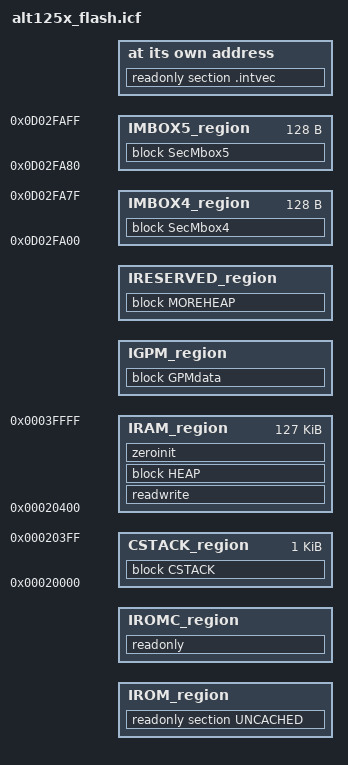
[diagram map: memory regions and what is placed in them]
/*###ICF### Section handled by ICF editor, don't touch! ****/
/*-Editor annotation file-*/
/* IcfEditorFile="$TOOLKIT_DIR$\config\ide\IcfEditor\cortex_v1_4.xml" */

include "defs.icf";

/* The base address for MCU firmware on flash */
define symbol __MCU_MTD_PARTITION_BASE__ = 0x08000000;
export symbol __MCU_MTD_PARTITION_BASE__;

/* The header size for MCU firmware */
define symbol __HEADER_SIZE__ = 0x200;

/* An instruction cache is present on the I-CODE bus for
 * address 0x1000_0000 to 0x1FFF_FFFF whereas
 * address 0x0000_0000 to 0x0FFF_FFFF is used for direct instruction fetching. */


/* Reserve a memory region for the .uncached section (direct access) */
define symbol __UNCACHED_SIZE__ = 0x400;
define symbol __UNCACHED_ORIGIN__ = __MCU_MTD_PARTITION_BASE__ + __MCU_MTD_PARTITION_OFFSET__ + __HEADER_SIZE__;

/* To leverage instruction cache, use address 0x1000_0000 to 0x1FFF_FFFF */
define symbol __FLASH_ORIGIN__ = __UNCACHED_ORIGIN__ + __UNCACHED_SIZE__ + 0x10000000;
define symbol __FLASH_END__ = __FLASH_ORIGIN__ + __MCU_MTD_PARTITION_SIZE__ - __UNCACHED_SIZE__ - __HEADER_SIZE__ + 0x10000000 - 1;

/* A part of the GPM memory is used as an extended heap.
 * By defining __RESERVED_GPM_RAM_SIZE__, one can adjust the size of the second HEAP (default to half of the GPM RAM).
 */
if (!isdefinedsymbol(__RESERVED_GPM_RAM_SIZE__)) {
  define symbol __RESERVED_GPM_RAM_SIZE__ = __GPM_RAM_SIZE__ / 2;
}

/* The mermoy size for the mailbox. Internal use. */
define symbol __MBOX_MEM_LENGTH__ = 128;

/* The memory addresses for the mailbox. Internal use. */
define symbol __MBOX4_MEM_ORIGIN__ = 0x0D02FA00;
define symbol __MBOX5_MEM_ORIGIN__ = 0x0D02FA80;
define symbol __MBOX4_MEM_SIZE__ = __MBOX_MEM_LENGTH__;
define symbol __MBOX5_MEM_SIZE__ = __MBOX_MEM_LENGTH__;

/*-Sizes-*/
define symbol __ICFEDIT_size_cstack__     = 0x400;
define symbol __ICFEDIT_size_heap__       = 0x10000;

/*-Specials-*/
define symbol __ICFEDIT_intvec_start__ = __UNCACHED_ORIGIN__;

/*-Memory Regions-*/
define symbol __ICFEDIT_region_IROM1_start__   = __UNCACHED_ORIGIN__;
define symbol __ICFEDIT_region_IROM1_end__   = __UNCACHED_ORIGIN__ + __UNCACHED_SIZE__ - 1;
define symbol __ICFEDIT_region_IROM2_start__   = __FLASH_ORIGIN__;
define symbol __ICFEDIT_region_IROM2_end__   = __FLASH_END__;
define symbol __ICFEDIT_region_CSTACK_start__   = 0x20000;
define symbol __ICFEDIT_region_CSTACK_end__   = __ICFEDIT_region_CSTACK_start__ + __ICFEDIT_size_cstack__ - 1;
define symbol __ICFEDIT_region_IRAM1_start__   = __ICFEDIT_region_CSTACK_end__ + 1;
define symbol __ICFEDIT_region_IRAM1_end__   = 0x3ffff;
define symbol __ICFEDIT_region_IGPM_start__   = __GPM_RAM_BASE__;
define symbol __ICFEDIT_region_IGPM_end__   = __GPM_RAM_BASE__ + __GPM_RAM_SIZE__ - __RESERVED_GPM_RAM_SIZE__ - 1;
define symbol __ICFEDIT_region_IRESERVED_start__   = __GPM_RAM_BASE__ + __GPM_RAM_SIZE__ - __RESERVED_GPM_RAM_SIZE__;
define symbol __ICFEDIT_region_IRESERVED_end__   = __GPM_RAM_BASE__ + __GPM_RAM_SIZE__ - 1;
define symbol __ICFEDIT_region_IMBOX4_start__   = __MBOX4_MEM_ORIGIN__;
define symbol __ICFEDIT_region_IMBOX4_end__   = __MBOX4_MEM_ORIGIN__ + __MBOX4_MEM_SIZE__ - 1;
define symbol __ICFEDIT_region_IMBOX5_start__   = __MBOX5_MEM_ORIGIN__;
define symbol __ICFEDIT_region_IMBOX5_end__   = __MBOX5_MEM_ORIGIN__ + __MBOX5_MEM_SIZE__ - 1;

/**** End of ICF editor section. ###ICF###*/

define memory mem with size = 4G;
/* Memory region for direct code accesss (reserved for .uncached section) */
define region IROM_region   =   mem:[from __ICFEDIT_region_IROM1_start__ to __ICFEDIT_region_IROM1_end__];
/* Memory region for code access through instruction cache */
define region IROMC_region   =   mem:[from __ICFEDIT_region_IROM2_start__ to __ICFEDIT_region_IROM2_end__];
/* Internal SRAM */
define region CSTACK_region   =   mem:[from __ICFEDIT_region_CSTACK_start__ to __ICFEDIT_region_CSTACK_end__];
define region IRAM_region   =   mem:[from __ICFEDIT_region_IRAM1_start__ to __ICFEDIT_region_IRAM1_end__];
/* Retention RAM from GPM memory */
define region IGPM_region   =   mem:[from __ICFEDIT_region_IGPM_start__ to __ICFEDIT_region_IGPM_end__];
/* An extended heap from GPM memory */
define region IRESERVED_region   =   mem:[from __ICFEDIT_region_IRESERVED_start__ to __ICFEDIT_region_IRESERVED_end__];
/* Memory regions for the use of inter-processor communication */
define region IMBOX4_region   =   mem:[from __ICFEDIT_region_IMBOX4_start__ to __ICFEDIT_region_IMBOX4_end__];
define region IMBOX5_region   =   mem:[from __ICFEDIT_region_IMBOX5_start__ to __ICFEDIT_region_IMBOX5_end__];

define block CSTACK        with alignment = 8, size = __ICFEDIT_size_cstack__       { };
define block HEAP          with expanding size, alignment = 8, minimum size = __ICFEDIT_size_heap__       { };
define block MOREHEAP      with alignment = 8, expanding size       { };
/*
 * GPMdata section. Data put in GPMdata section are retained even when
 * MCU operates in standby mode.
 */
define block GPMdata       with alignment = 4       { section GPMdata };
define block SecMbox4      with alignment = 4, size = __MBOX4_MEM_SIZE__       { section SecMbox4 };
define block SecMbox5      with alignment = 4, size = __MBOX5_MEM_SIZE__       { section SecMbox5 };

do not initialize  { section .noinit, section GPMdata, section SecMbox4, section SecMbox5};
initialize by copy { readwrite };
if (isdefinedsymbol(__USE_DLIB_PERTHREAD))
{
  // Required in a multi-threaded application
  initialize by copy with packing = none { section __DLIB_PERTHREAD };
}

/* Place vector table in UNCACHED region */
place at address mem:__ICFEDIT_intvec_start__ { readonly section .intvec };


place in IROM_region {readonly section UNCACHED};
place in IROMC_region  { readonly };
place in CSTACK_region { block CSTACK };
place in IRAM_region  { readwrite, block HEAP, zeroinit };
place in IGPM_region  { block GPMdata };
place in IRESERVED_region  { block MOREHEAP };
place in IMBOX4_region  { block SecMbox4 };
place in IMBOX5_region  { block SecMbox5 };
